VERSION ""

NS_ :

BS_:
BU_:
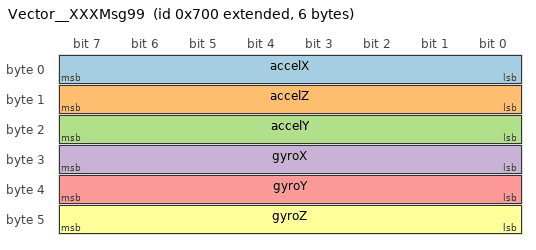
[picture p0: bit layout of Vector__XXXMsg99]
BO_ 2147485440 Vector__XXXMsg99: 6 Vector__XXX
   SG_ accelX : 7|8@0+ (1,0) [0|1] "" Vector__XXX
   SG_ accelZ : 15|8@0+ (1,0) [0|1] "" Vector__XXX
   SG_ accelY : 23|8@0+ (1,0) [0|1] "" Vector__XXX
   SG_ gyroX : 31|8@0- (1,0) [-12.5|12.5] "degree" Vector__XXX
   SG_ gyroY : 39|8@0- (1,0) [-12.5|12.5] "deg" Vector__XXX
   SG_ gyroZ : 47|8@0- (1,0) [-12.5|12.5] "dick" Vector__XXX

BO_ 2147485520 Msg278: 6 Vector__XXX

BA_DEF_ BO_ "GenMsgBackgroundColor" STRING ;
BA_DEF_ BO_ "GenMsgForegroundColor" STRING ;
BA_DEF_ BO_ "filterlabeling" INT 0 0;
BA_DEF_DEF_ "GenMsgBackgroundColor" "#ffffff";
BA_DEF_DEF_ "GenMsgForegroundColor" "#000000";
BA_DEF_DEF_ "filterlabeling" 1;
